# psc3_p8_ppca register map
Vendor: Infineon Technologies; Series: PSC3_P8; File version: 1.0
CPU: CM33 r0p1, little endian, MPU, FPU, DSP, VTOR, 3 interrupt priority bits, 143 interrupts
Registers are 32-bit, read-write, reset 0x0 unless marked. A register's access mark holds for its fields unless they carry their own. Offsets are from the block's base; [hi:lo] are bit positions; lines under a group give offsets from that group; {n}, {i} and the like mark numbered series; 'fields as' and 'values as' point back to an identical list; <NAME> marks a mode.

## SRSS (part 1 of 2) — SRSS Core Registers
Base 0x68200000
0x40 PWR_LVD_STATUS ro — High Voltage / Low Voltage Detector (HVLVD) Status Register
  [0] HVLVD1_OK — HVLVD1 output. 0: below voltage threshold 1: above voltage threshold
{0x100+4i} CLK_DSI_SELECT[{i}] (i=0..15) — Clock DSI Select Register
  [4:0] DSI_MUX — Selects a DSI source or low frequency clock for use in a clock path. The output of this mux can be selected for clock PATH<i> using CLK_SELECT_PATH register. Using the output of this mux as HFCLK source will result in undefined behavior. It can be used to clocks to DSI or as reference inputs for the FLL/PLL, subject to the frequency limits of those circuits. This mux is not glitch free, so do not change the selection while it is an actively selected clock.
    {v}=DSI_OUT{v} (DSI{v} - dsi_out[{v}]) (v=0..15); 16=ILO (ILO - Internal Low-speed Oscillator #0); 17=WCO (WCO - Watch-Crystal Oscillator); 18=ALTLF (ALTLF - Alternate Low-Frequency Clock); 19=PILO (PILO - Precision Internal Low-speed Oscillator); 20=ILO1 (ILO1 - Internal Low-speed Oscillator #1, if present.)
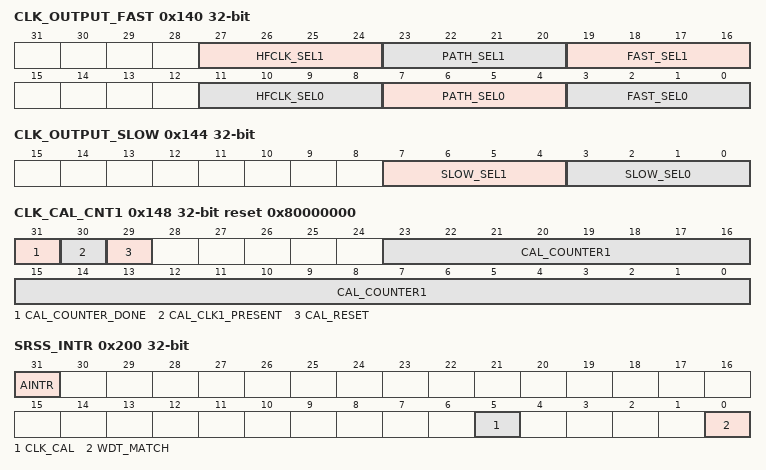
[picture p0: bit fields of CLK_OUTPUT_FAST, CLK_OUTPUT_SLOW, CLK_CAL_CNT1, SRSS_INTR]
0x140 CLK_OUTPUT_FAST — Fast Clock Output Select Register
  [27:24] HFCLK_SEL1 — Selects a HFCLK tree for use in fast clock output #1 logic
  [23:20] PATH_SEL1 — Selects a clock path to use in fast clock output #1 logic.
  [19:16] FAST_SEL1 — Select signal for fast clock output #1
    0=NC (Disabled - output is 0. For power savings, clocks are blocked before entering any muxes, including PATH_SEL1 and HFCLK_SEL1.); 1=ECO (External Crystal Oscillator (ECO)); 2=EXTCLK (External clock input (EXTCLK)); 3=ALTHF (Alternate High-Frequency (ALTHF) clock input to SRSS); 4=TIMERCLK (Timer clock. It is grouped with the fast clocks because it may be a gated version of a fast clock, and therefore may have a short high pulse.); 5=PATH_SEL1 (Selects the clock path chosen by PATH_SEL1 field); 6=HFCLK_SEL1 (Selects the output of the HFCLK_SEL1 mux); 7=SLOW_SEL1 (Selects the output of CLK_OUTPUT_SLOW.SLOW_SEL1); 8=IHO (Internal High-speed Oscillator (IHO).); 9=PWR (clk_pwr: used for PPU and related components)
  [11:8] HFCLK_SEL0 — Selects a HFCLK tree for use in fast clock output #0
  [7:4] PATH_SEL0 — Selects a clock path to use in fast clock output #0 logic.
  [3:0] FAST_SEL0 — Select signal for fast clock output #0
    0=NC (Disabled - output is 0. For power savings, clocks are blocked before entering any muxes, including PATH_SEL0 and HFCLK_SEL0.); 1=ECO (External Crystal Oscillator (ECO)); 2=EXTCLK (External clock input (EXTCLK)); 3=ALTHF (Alternate High-Frequency (ALTHF) clock input to SRSS); 4=TIMERCLK (Timer clock. It is grouped with the fast clocks because it may be a gated version of a fast clock, and therefore may have a short high pulse.); 5=PATH_SEL0 (Selects the clock path chosen by PATH_SEL0 field); 6=HFCLK_SEL0 (Selects the output of the HFCLK_SEL0 mux); 7=SLOW_SEL0 (Selects the output of CLK_OUTPUT_SLOW.SLOW_SEL0); 8=IHO (Internal High-speed Oscillator (IHO).); 9=PWR (clk_pwr: used for PPU and related components)
0x144 CLK_OUTPUT_SLOW — Slow Clock Output Select Register
  [7:4] SLOW_SEL1 — Select signal for slow clock output #1
    0=NC (Disabled - output is 0. For power savings, clocks are blocked before entering any muxes.); 1=ILO (Internal Low Speed Oscillator (ILO)); 2=WCO (Watch-Crystal Oscillator (WCO)); 3=BAK (Root of the Backup domain clock tree (BAK)); 4=ALTLF (Alternate low-frequency clock input to SRSS (ALTLF)); 5=LFCLK (Root of the low-speed clock tree (LFCLK)); 6=IMO (Internal Main Oscillator (IMO). This is grouped with the slow clocks so it can be observed during DEEPSLEEP entry/exit.); 7=SLPCTRL (Sleep Controller clock (SLPCTRL). This is grouped with the slow clocks so it can be observed during DEEPSLEEP entry/exit.); 8=PILO (Precision Internal Low Speed Oscillator (PILO)); 9=ILO1 (Internal Low Speed Oscillator (ILO1), if present on the product.); 10=ECO_PRESCALER (ECO Prescaler (ECO_PRESCALER)); 11=LPECO; 12=LPECO_PRESCALER (LPECO Prescaler (LPECO_PRESCALER)); 13=MFO (Medium Frequency Oscillator (MFO))
  [3:0] SLOW_SEL0 — Select signal for slow clock output #0
    values as SLOW_SEL1
0x148 CLK_CAL_CNT1 reset 0x80000000 — Clock Calibration Counter 1
  [31] CAL_COUNTER_DONE ro — Status bit indicating that the internal counter #1 is finished counting and CLK_CAL_CNT2.COUNTER stopped counting up
  [30] CAL_CLK1_PRESENT ro — Status bit indicating that a posedge was detected by counter #1. If this bit never asserts, there is no clock on counter #1 and CAL_COUNTER_DONE will stay low indefinitely. This can be recovered with CAL_RESET.
  [29] CAL_RESET — Reset clock calibration logic for window mode. This can be used to recover from unexpected conditions, such as no clock present on counter #1. Set this bit only when CLK_CAL_TEST.CAL_WINDOW_SEL=1 (window mode). It takes 3 clock cycles for reset to propagate.
  [23:0] CAL_COUNTER1 — Down-counter clocked on fast clock output #0 (see CLK_OUTPUT_FAST). This register always reads as zero. Counting starts internally when this register is written with a nonzero value. CAL_COUNTER_DONE goes immediately low to indicate that the counter has started and will be asserted when the counters are done. Do not write this field unless CAL_COUNTER_DONE==1. Both clocks must be running or the measurement will not complete, and this case can be recovered using CAL_RESET.
0x14C CLK_CAL_CNT2 ro — Clock Calibration Counter 2
  [23:0] CAL_COUNTER2 — Up-counter clocked on fast clock output #1 (see CLK_OUTPUT_FAST). When CLK_CAL_CNT1.CAL_COUNTER_DONE==1, the counter is stopped and can be read by SW. Do not read this value unless CAL_COUNTER_DONE==1. The expected final value is related to the ratio of clock frequencies used for the two counters and the value loaded into counter 1: CLK_CAL_CNT2.COUNTER=(F_cnt2/F_cnt1)*(CLK_CAL_CNT1.COUNTER)
0x200 SRSS_INTR — SRSS Interrupt Register
  [31] AINTR ro — See additional interrupts in SRSS_AINTR.
  [5] CLK_CAL write-1-clears — Clock calibration counter is done. This field is reset during DEEPSLEEP mode.
  [0] WDT_MATCH write-1-clears — WDT Interrupt Request. This bit is set each time WDT_COUNTR==WDT_MATCH. W1C also feeds the watch dog. Missing 2 interrupts in a row will generate a reset. Due to internal synchronization, it takes 2 SYSCLK cycles to update after a W1C. Interrupt state for WDT_MATCH remains valid throughout hibernate.
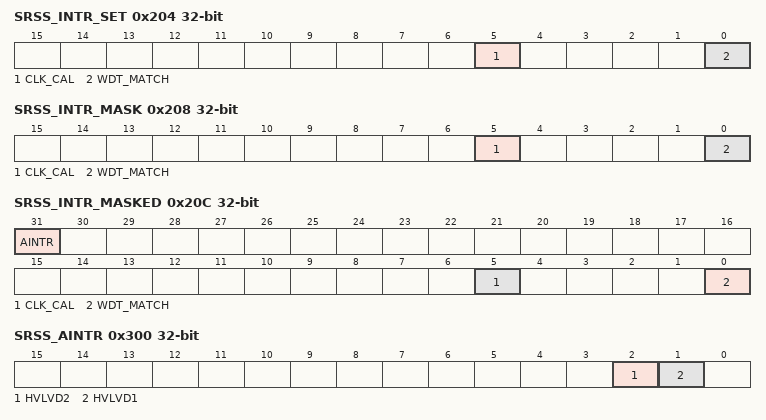
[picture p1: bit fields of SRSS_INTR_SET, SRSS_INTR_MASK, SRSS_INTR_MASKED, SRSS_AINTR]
0x204 SRSS_INTR_SET — SRSS Interrupt Set Register
  [5] CLK_CAL write-1-sets — Set interrupt for clock calibration counter done. This field is reset during DEEPSLEEP mode.
  [0] WDT_MATCH write-1-sets — Set interrupt for low voltage detector WDT_MATCH Interrupt state for WDT_MATCH remains valid throughout hibernate.
0x208 SRSS_INTR_MASK — SRSS Interrupt Mask Register
  [5] CLK_CAL — Mask for clock calibration done
  [0] WDT_MATCH — Mask for watchdog timer. Clearing this bit will not forward the interrupt to the CPU. It will not, however, disable the WDT reset generation on 2 missed interrupts. When WDT resets the chip, it also internally pends an interrupt that survives the reset. To prevent unintended ISR execution, clear SRSS_INTR.WDT_MATCH before setting this bit.
0x20C SRSS_INTR_MASKED ro — SRSS Interrupt Masked Register
  [31] AINTR — See additional MASKED bits in SRSS_AINTR_MASKED.ADDITIONAL
  [5] CLK_CAL — Logical and of corresponding request and mask bits.
  [0] WDT_MATCH — Logical and of corresponding request and mask bits.
0x300 SRSS_AINTR — SRSS Additional Interrupt Register
  [2] HVLVD2 write-1-clears — Interrupt for low voltage detector HVLVD2
  [1] HVLVD1 write-1-clears — Interrupt for low voltage detector HVLVD1
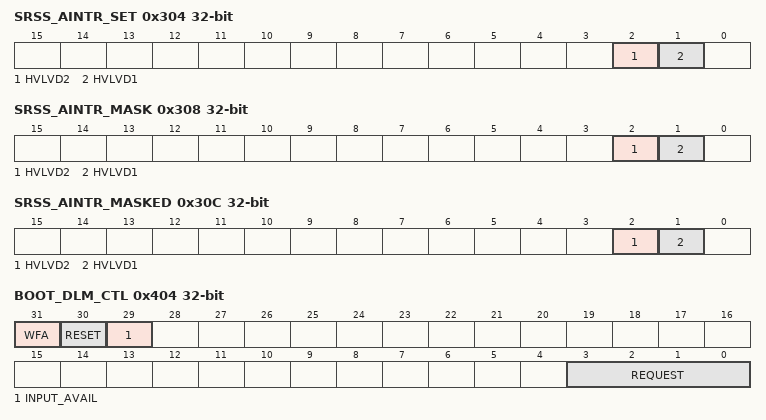
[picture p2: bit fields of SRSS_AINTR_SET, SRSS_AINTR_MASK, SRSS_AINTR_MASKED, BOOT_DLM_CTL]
0x304 SRSS_AINTR_SET — SRSS Additional Interrupt Set Register
  [2] HVLVD2 write-1-sets — Set interrupt for low voltage detector HVLVD2
  [1] HVLVD1 write-1-sets — Set interrupt for low voltage detector HVLVD1
0x308 SRSS_AINTR_MASK — SRSS Additional Interrupt Mask Register
  [2] HVLVD2 — Mask for low voltage detector HVLVD2
  [1] HVLVD1 — Mask for low voltage detector HVLVD1
0x30C SRSS_AINTR_MASKED ro — SRSS Additional Interrupt Masked Register
  [2] HVLVD2 — Logical and of corresponding request and mask bits.
  [1] HVLVD1 — Logical and of corresponding request and mask bits.
0x404 BOOT_DLM_CTL — Debug Control Register
  [31] WFA — Wait for Action. Set by BootROM when it waits for application or debug certificate to be loaded into the RAM. The bit must be cleared to continue BootROM operation. It is used by the Sys-AP.
  [30] RESET — Request the device reset after RAM application complete input parameters processing. This bit is analyzed with APP_INPUT_AVAIL so to take effect write both. 0 - No action, the device waits for input parameters. 1 - Reset the device after input parameters processing complete.
  [29] INPUT_AVAIL — Notify RAM application that input parameters are valid for processing: 0 - the input parameters are not available. 1 - the input parameters are available (ready) for processing.
  [3:0] REQUEST — A request to ROM_BOOT FW to execute particular code. This field survives some resets, including a system reset: * 0 - No request (default). * 1 - ROM_BOOT to wait for DLM app (PC=0). * 2 - ROM_BOOT to wait for an OEM debug token. * 3 - ROM_BOOT to wait for a PROT_FW debug token. * 4, 5 - ignored by ROM_BOOT. * 6 - ROM_BOOT to launch DLM app which has been downloaded by DFU. * 7 - ROM_BOOT to respond to DFU with DLM app status. Other: ignored by ROM_BOOT.
0x408 BOOT_DLM_CTL2 — Debug Control Register 2
  [31:0] APP_CTL — Address of application descriptor or debug certificate depends on DEBUG_TST_CTL.REQUEST. The application descriptor provides info about RAM application and its parameters layout in the staging area to BootROM and RAM application itself
0x40C BOOT_DLM_STATUS — Debug Status Register
  [31:0] DEBUG_STATUS — RAM application execution status. This status can be read by the debugger using Sys-AP or user application when RAM application completes with system reset. This field survives some resets, including a system reset.
0x410 RES_SOFT_CTL — Soft Reset Trigger Register
  [0] TRIGGER_SOFT write-1-sets — Triggers a soft reset. The reset clears this bit.
0x418 BOOT_STATUS — Boot Execution Status Register
  [31:0] DEBUG_STATUS — Boot execution status. This status register can be used for communication between ROM_BOOT and User Application. This status can be read by the debugger using Sys-AP or User Application. This field survives some resets, including a system reset.
0x430 BOOT_ENTRY — Warm Boot Entry Address
  [31:0] WARM_BOOT_ENTRY — Warm boot entry point. This status register can be used for communication between 2 software application before/after DS-RAM, DS-OFF or soft reset. This field survives low voltage resets, including a system reset.
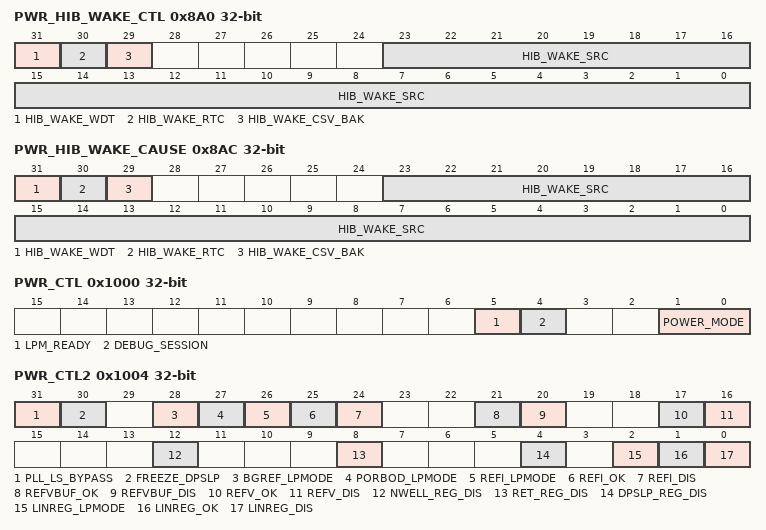
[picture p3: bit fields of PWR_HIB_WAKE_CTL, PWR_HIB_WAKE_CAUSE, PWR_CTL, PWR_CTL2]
0x8A0 PWR_HIB_WAKE_CTL — Hibernate Wakeup Mask Register
  [31] HIB_WAKE_WDT — When set, HIBERNATE will wakeup for a pending WDT interrupt.
  [30] HIB_WAKE_RTC — When set, HIBERNATE will wakeup for a pending RTC interrupt.
  [29] HIB_WAKE_CSV_BAK — When set, HIBERNATE will wakeup for CSV_BAK detection.
  [23:0] HIB_WAKE_SRC — When set, HIBERNATE will wakeup for the assigned source.
0x8A4 PWR_HIB_WAKE_CTL2 — Hibernate Wakeup Polarity Register
  [23:0] HIB_WAKE_SRC — Each bit selects the polarity for the corresponding HIBERNATE wakeup source. 0: Wakes when unmasked input is 0. 1: Wakes when unmasked input is 1.
0x8AC PWR_HIB_WAKE_CAUSE — Hibernate Wakeup Cause Register
  [31] HIB_WAKE_WDT write-1-clears — Indicates WDT wakeup cause. The WDT interrupt must be cleared before this bit can be cleared.
  [30] HIB_WAKE_RTC write-1-clears — Indicates RTC wakeup cause. The RTC interrupt must be cleared before this bit can be cleared.
  [29] HIB_WAKE_CSV_BAK write-1-clears — Indicates CSV_BAK wakeup cause. The related fault must be handled before this bit can be cleared.
  [23:0] HIB_WAKE_SRC write-1-clears — Each bit indicates a HIBERNATE wakeup cause. For each bit, writing a 1 clears the cause flag.
0x1000 PWR_CTL ro — Power Mode Control
  [5] LPM_READY — Indicates whether certain low power functions are ready. The low current circuits take longer to startup after XRES, HIBERNATE wakeup, or supply supervision reset wakeup than the normal mode circuits. HIBERNATE mode may be entered regardless of this bit. 0: If a low power circuit operation is requested, it will stay in its normal operating mode until it is ready. If DEEPSLEEP is requested by all processors WFI/WFE, the device will instead enter SLEEP. When low power circuits are ready, device will automatically enter the originally requested mode. 1: Normal operation. DEEPSLEEP and low power circuits operate as requested in other registers.
  [4] DEBUG_SESSION — Indicates whether a debug session is active (CDBGPWRUPREQ signal is 1)
    0=NO_SESSION (No debug session active); 1=SESSION_ACTIVE (Debug session is active. Power modes behave differently to keep the debug session active, and current consumption may be higher than datasheet specification.)
  [1:0] POWER_MODE — Current power mode of the device. Note that this field cannot be read in all power modes on actual silicon.
    0=RESET (System is resetting.); 1=ACTIVE (At least one CPU is running.); 2=SLEEP (No CPUs are running. Peripherals may be running.); 3=DEEPSLEEP (Main high-frequency clock is off; low speed clocks are available. Communication interface clocks may be present.)
0x1004 PWR_CTL2 — Power Mode Control 2
  [31] PLL_LS_BYPASS — Bypass level shifter inside the PLL. Unused, if no PLL is present in the product. Note that this only applies to PLL200M. 0: Do not bypass the level shifter. This setting is ok for all operational modes and vccd target voltage. 1: Bypass the level shifter. This may reduce jitter on the PLL output clock, but can only be used when vccd is targeted to 1.1V nominal. Otherwise, it can result in clock degradation and static current.
  [30] FREEZE_DPSLP write-1-clears — Controls whether mode and state of GPIOs and SIOs in the system are frozen. This is intended to be used as part of the DEEPSLEEP-RAM and DEEPSLEEP-OFF entry and exit sequences. It is set by HW while entering DEEPSLEEP-RAM and DEEPSLEEP-OFF modes. Writing a 1 clears freeze and GPIOs and SIOs resume normal operation.
  [28] BGREF_LPMODE — Control the circuit-level power mode of the Bandgap Reference circuits for higher operating modes than DEEPSLEEP. This selects a second set of bandgap voltage and current generation circuits that are optimized for low current consumption. The low current circuits are automatically used in DEEPSLEEP mode regardless of this bit. The value in this register is ignored and higher-current mode is used until LPM_READY==1. After this bit is set, the Active Reference circuit can be disabled to reduce current (ACT_REF_DIS=0). Firmware is responsible to enable the Active Reference and ensure ACT_REF_OK==1 before changing back to higher current mode. This register is only reset by XRES, HIBERNATE wakeup, or supply supervision reset. 0: Bandgap Reference uses the normal settings. 1: Bandgap Reference uses the low power DeepSleep circuits. Power supply rejection is reduced to save current.
  [27] PORBOD_LPMODE — Control the power mode of the POR/BOD circuits. The value in this register is ignored and normal mode is used until LPM_READY==1. This register is only reset by XRES, HIBERNATE wakeup, or supply supervision reset. 0: POR/BOD circuits operate in normal mode. 1: POR/BOD circuits operate in low power mode. Response time is reduced to save current.
  [26] REFI_LPMODE — Control the power mode of the reference current generator. The value in this register is ignored and normal mode is used until LPM_READY==1. This register is only reset by XRES, HIBERNATE wakeup, or supply supervision reset. 0: Current reference generator operates in normal mode. 1: Current reference generator operates in low power mode. Response time is reduced to save current.
  [25] REFI_OK ro — Indicates that the current reference is ready. Due to synchronization delays, it may take two IMO clock cycles for hardware to clear this bit after asserting REFI_DIS=1.
  [24] REFI_DIS
  [21] REFVBUF_OK ro — Indicates that the voltage reference buffer is ready. Due to synchronization delays, it may take two IMO clock cycles for hardware to clear this bit after asserting REFVBUF_DIS=1.
  [20] REFVBUF_DIS — Disable the voltage reference buffer. Firmware should only disable the buffer when there is no connected circuit that is using it. SRSS circuits that require it are the PLL and ECO. A particular product may have circuits outside the SRSS that use the buffer. This register is only reset by XRES, HIBERNATE wakeup, or supply supervision reset.
  [17] REFV_OK ro — Indicates that the normal mode of the voltage reference is ready.
  [16] REFV_DIS
  [12] NWELL_REG_DIS — Explicitly disable the Nwell regulator. This register should normally be zero, except for special sequences provided by Infineon to use a different regulator. This register is only reset by XRES, HIBERNATE wakeup, or supply supervision reset. 0: Nwell Regulator is on. Hardware disables it automatically for internal sequences, including for HIBERNATE and XRES low power modes. Hardware keeps the Nwell Regulator enabled during ACTIVE/SLEEP modes, so it is ready to enter DEEPSLEEP at any time. 1: Nwell Regulator is explicitly disabled. Only use this for special cases when another source supplies vnwell during DEEPSLEEP mode. This setting is only legal when another source supplies vnwell, but there is no special hardware protection for this case.
  [8] RET_REG_DIS — Explicitly disable the Retention regulator. This field should normally be zero, except for special sequences provided by Infineon to use a different regulator. This register is only reset by XRES, HIBERNATE wakeup, or supply supervision reset. 0: Retention Regulator is not explicitly disabled. Hardware disables it automatically for internal sequences, including for HIBERNATE and XRES low power modes. Hardware keeps the Retention Regulator enabled during ACTIVE/SLEEP modes, so it is ready to enter DEEPSLEEP at any time. 1: Retention Regulator is explicitly disabled. Only use this for special cases when another source supplies vccret during DEEPSLEEP mode. This setting is only legal when another source supplies vccret, but there is no special hardware protection for this case.
  [4] DPSLP_REG_DIS — Explicity disable the DeepSleep regulator, including circuits shared with the Active Regulator. This register must not be set except as part of an Infineon-provided sequence or API. This register is only reset by XRES, HIBERNATE wakeup, or supply supervision reset. 0: DeepSleep Regulator is not explicitly disabled. This is the normal setting, and hardware automatically controls the DeepSleep regulator for most sequences, including for HIBERNATE and XRES low power modes. This setting must be used if the Active Linear Regulator is used, because some circuitry is shared. 1: DeepSleep Regulator is explicitly disabled. Only use this for special cases as part of an Infineon-provided handoff to another supply source. For example, this setting may be used when another source supplies vccdpslp during DEEPSLEEP mode and the Active Linear Regulator is not usedfor ACTIVE/SLEEP modes.
  [2] LINREG_LPMODE — Control the power mode of the Linear Regulator. The value in this register is ignored and normal mode is used until LPM_READY==1. This register is only reset by XRES, HIBERNATE wakeup, or supply supervision reset. 0: Linear Regulator operates in normal mode. 1: Linear Regulator operates in low power mode. Load current capability is reduced, and firmware must ensure the current is kept within the limit.
  [1] LINREG_OK ro — Status of the linear Core Regulator.
  [0] LINREG_DIS — Explicitly disable the linear Core Regulator. Write zero for Traveo II devices. This register is only reset by XRES, HIBERNATE wakeup, or supply supervision reset. 0: Linear Core Regulator is not explicitly disabled. Hardware disables it automatically for internal sequences, including for DEEPSLEEP, HIBERNATE, and XRES low power modes. 1: Linear Core Regulator is explicitly disabled. Only use this for special cases when another source supplies vccd during ACTIVE and SLEEP modes. This setting is only legal when another source supplies vccd, but there is no special hardware protection for this case.
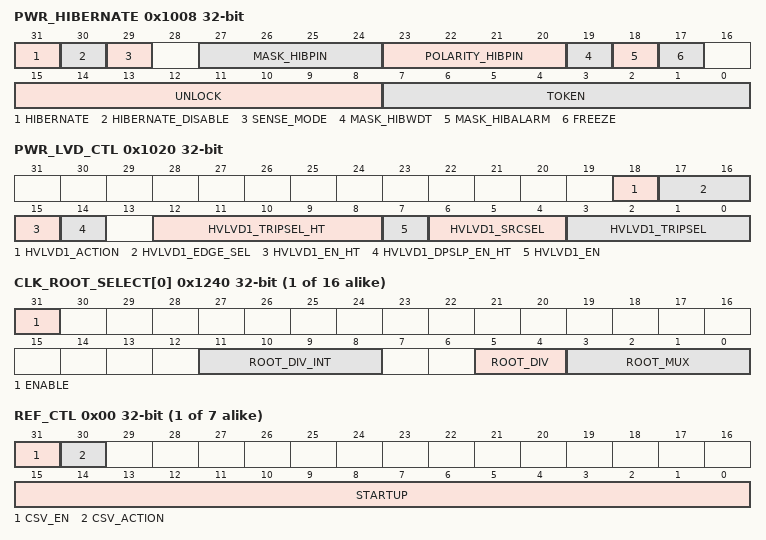
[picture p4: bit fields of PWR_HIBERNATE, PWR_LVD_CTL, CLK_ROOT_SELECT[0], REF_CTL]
0x1008 PWR_HIBERNATE — HIBERNATE Mode Register
  [31] HIBERNATE — Firmware sets this bit to enter HIBERNATE mode. The system will enter HIBERNATE mode immediately after writing to this bit and will wakeup only in response to XRES or WAKEUP. Both UNLOCK and FREEZE must have been set correctly in a previous write operations. Otherwise, it will not enter HIBERNATE. External supplies must have been stable for 250us before entering HIBERNATE mode.
  [30] HIBERNATE_DISABLE write-1-sets — Hibernate disable bit. 0: Normal operation, HIBERNATE works as described 1: Further writes to this register are ignored Note: This bit is a write-once bit until the next reset. Avoid changing any other bits in this register while disabling HIBERNATE mode. Also, it is recommended to clear the UNLOCK code, if it was previously written..
  [29] SENSE_MODE write-1-sets — Power mode when wakeups are sensitive. The default of this field is 0 for software compatibility with other products. It is recommended to set this field to 1 for new/updated software. 0: Wakeups are sensitive only during HIBERNATE mode. A wakeup pulse that comes just before HIBERNATE entry may be missed. Backward compatible. 1: Wakeups are sensitive in HIBERNATE and higher modes. Before entering HIBERNATE, software must clear all unmasked, pending wakeups in PWR_HIB_WAKE_CAUSE register. An unmasked, pending wakeup causes HIBERNATE wakeup, even if it was pending from before HIBERNATE entry. This prevents missed wakeups.
  [27:24] MASK_HIBPIN
  [23:20] POLARITY_HIBPIN
  [19] MASK_HIBWDT
  [18] MASK_HIBALARM
  [17] FREEZE — Controls whether mode and state of GPIOs and SIOs in the system are frozen. This is intended to be used as part of the HIBERNATE entry and exit sequences. When entering HIBERNATE mode, the first write instructs DEEPSLEEP peripherals that they cannot ignore the upcoming freeze command. This occurs even in the illegal condition where UNLOCK is not set. If UNLOCK and HIBERNATE are properly set, the IOs actually freeze on the second write. Supply supervision is disabled during HIBERNATE mode. HIBERNATE peripherals ignore resets (excluding XRES) while FREEZE==1.
  [15:8] UNLOCK — This byte must be set to 0x3A for FREEZE or HIBERNATE fields to operate. Any other value in this register will cause FREEZE/HIBERNATE to have no effect, except as noted in the FREEZE description.
  [7:0] TOKEN — Contains a 8-bit token that is retained through a HIBERNATE/WAKEUP sequence that can be used by firmware to differentiate WAKEUP from a general RESET event. Note that waking up from HIBERNATE using XRES will reset this register.
0x1020 PWR_LVD_CTL — High Voltage / Low Voltage Detector (HVLVD) Configuration Register
  [18] HVLVD1_ACTION — Action taken when the threshold is crossed in the programmed directions(s)
    0=INTERRUPT (Generate an interrupt); 1=FAULT (Generate a fault)
  [17:16] HVLVD1_EDGE_SEL — Sets which edge(s) will trigger an action when the threshold is crossed.
    0=DISABLE (Disabled); 1=RISING (Rising edge); 2=FALLING (Falling edge); 3=BOTH (Both rising and falling edges)
  [15] HVLVD1_EN_HT — Enable HVLVD1 voltage monitor. This detector monitors vddd only. Do not change other HVLVD1 settings when enabled.
  [14] HVLVD1_DPSLP_EN_HT — Keep HVLVD1 voltage monitor enabled during DEEPSLEEP mode. This field is only used when HVLVD1_EN_HT==1.
  [12:8] HVLVD1_TRIPSEL_HT
  [7] HVLVD1_EN — Enable HVLVD1 voltage monitor. HVLVD1 does not function during DEEPSLEEP, but it automatically returns to its configured setting after DEEPSLEEP wakeup. Do not change other HVLVD1 settings when enabled.
  [6:4] HVLVD1_SRCSEL — Source selection for HVLVD1
    0=VDDD (Select VDDD); 1=AMUXBUSA (Select AMUXBUSA (VDDD branch)); 2=RSVD (N/A); 3=VDDIO (N/A); 4=AMUXBUSB (Select AMUXBUSB (VDDD branch))
  [3:0] HVLVD1_TRIPSEL — Threshold selection for HVLVD1. Disable the detector (HVLVD1_EN=0) before changing the threshold. 0: rise=1.225V (nom), fall=1.2V (nom) 1: rise=1.425V (nom), fall=1.4V (nom) 2: rise=1.625V (nom), fall=1.6V (nom) 3: rise=1.825V (nom), fall=1.8V (nom) 4: rise=2.025V (nom), fall=2V (nom) 5: rise=2.125V (nom), fall=2.1V (nom) 6: rise=2.225V (nom), fall=2.2V (nom) 7: rise=2.325V (nom), fall=2.3V (nom) 8: rise=2.425V (nom), fall=2.4V (nom) 9: rise=2.525V (nom), fall=2.5V (nom) 10: rise=2.625V (nom), fall=2.6V (nom) 11: rise=2.725V (nom), fall=2.7V (nom) 12: rise=2.825V (nom), fall=2.8V (nom) 13: rise=2.925V (nom), fall=2.9V (nom) 14: rise=3.025V (nom), fall=3.0V (nom) 15: rise=3.125V (nom), fall=3.1V (nom)
{0x1200+4i} CLK_PATH_SELECT[{i}] (i=0..15) — Clock Path Select Register
  [2:0] PATH_MUX — Selects a source for clock PATH<i>. Note that not all products support all clock sources. Selecting a clock source that is not supported will result in undefined behavior. It takes four cycles of the originally selected clock to switch away from it. Do not disable the original clock during this time.
    0=IMO (IMO - Internal R/C Oscillator); 1=EXTCLK (EXTCLK - External Clock Pin); 2=ECO (ECO - External-Crystal Oscillator); 3=ALTHF (ALTHF - Alternate High-Frequency clock input (product-specific clock)); 4=DSI_MUX (DSI_MUX - Output of DSI mux for this path. Using a DSI source directly as root of HFCLK will result in undefined behavior.); 5=LPECO (LPECO - Low-Power External-Crystal Oscillator); 6=IHO (IHO - Internal High-speed Oscillator)
{0x1240+4i} CLK_ROOT_SELECT[{i}] (i=0..15) — Clock Root Select Register
  [31] ENABLE — Enable for this clock root. All clock roots default to disabled (ENABLE==0) except HFCLK0, which cannot be disabled.
  [11:8] ROOT_DIV_INT — Selects predivider value for this clock root and DSI input. This divider is after DIRECT_MUX. For products with DSI, the output of this mux is routed to DSI for use as a signal. For products with clock supervision, the output of this mux is the monitored clock for CSV_HF<k>.
    0=NO_DIV (Transparent mode, feed through selected clock source w/o dividing.); {v}=DIV_BY_{v+1} (Divide selected clock source by {v+1}) (v=1..15)
  [5:4] ROOT_DIV — Obsolete. Do not use in new designs.
  [3:0] ROOT_MUX — Selects a clock path for HFCLK<k> and SRSS DSI input <k>. The output of this mux goes to the direct mux (see CLK_DIRECT_SELECT). Use CLK_SELECT_PATH[i] to configure the desired path. The number of clock paths is product-specific, and selecting an unimplemented path is not supported. Some paths may have FLL or PLL available (product-specific), and the control and bypass mux selections of these are in other registers. Configure the FLL using CLK_FLL_CONFIG register. Configure a PLL using the related CLK_PLL_CONFIG[k] register. Note that not all products support all clock sources. Selecting a clock source that is not supported will result in undefined behavior. It takes four cycles of the originally selected clock to switch away from it. Do not disable the original clock during this time.
    {v}=PATH{v} (Select PATH{v}) (v=0..15)
{0x1280+4i} CLK_DIRECT_SELECT[{i}] (i=0..15) — Clock Root Direct Select Register
  [8] DIRECT_MUX — Direct selection mux that allows IMO to bypass most of the clock mux structure. For products with multiple regulators, this mux can be used to reduce current without requiring significant reconfiguration of the clocking network. The default value of HFCLK<0>==ROOT_MUX, and the default value for other clock trees is product-specific.
    0=IMO (Select IMO); 1=ROOT_MUX (Select ROOT_MUX selection)
0x1400 CSV_HF group — Clock Supervisor (CSV) registers for Root clocks
  {0x0+0x10*j} CSV[{j}] (j=0..6) group — Active domain Clock Supervisor (CSV) registers
    0x00 REF_CTL — Clock Supervision Reference Control
      [31] CSV_EN — Enables clock supervision, both frequency and loss. CSV in Active domain: Clock supervision is reset during DeepSleep and Hibernate modes. When enabled it begins operating automatically after a DeepSleep wakeup, but it must be reconfigured after Hibernate wakeup. CSV in DeepSleep domain: Clock supervision is reset during Hibernate mode. It must be reconfigured after Hibernate wakeup. A CSV error detection is reported to the Fault structure, or instead it can generate a power reset.
      [30] CSV_ACTION — Specifies the action taken when an anomaly is detected on the monitored clock. CSV in DeepSleep domain always do a Fault report (which also wakes up the system).
        0=FAULT (Generate a fault); 1=RESET (Cause a power reset. This should only be used for clk_hf0.)
      [15:0] STARTUP — Startup delay time -1 (in reference clock cycles), after enable or DeepSleep wakeup, from reference clock start to monitored clock start. At a minimum (both clocks running): STARTUP >= (PERIOD +3) * FREQ_RATIO - UPPER, with FREQ_RATIO = (Reference frequency / Monitored frequency) On top of that the actual clock startup delay and the margin for accuracy of both clocks must be added.
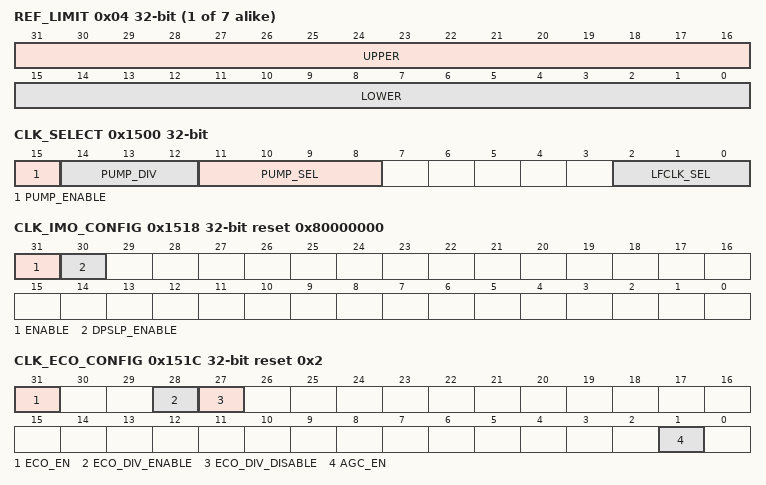
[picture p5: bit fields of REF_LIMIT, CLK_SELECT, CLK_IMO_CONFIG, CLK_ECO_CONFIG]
    0x04 REF_LIMIT — Clock Supervision Reference Limits
      [31:16] UPPER — Cycle time upper limit. Set the upper limit -1, in reference clock cycles, before (or same time) the next monitored clock event must happen. If a monitored clock event does not happen before this limit is reached, or does not happen at all (clock loss), a CSV error is detected.
      [15:0] LOWER — Cycle time lower limit. Set the lower limit -1, in reference clock cycles, before the next monitored clock event is allowed to happen. If a monitored clock event happens before this limit is reached a CSV error is detected. LOWER must be at least 1 less than UPPER. In case the clocks are asynchronous LOWER must be at least 3 less than UPPER.
    0x08 MON_CTL — Clock Supervision Monitor Control
      [15:0] PERIOD — Period time. Set the Period -1, in monitored clock cycles, before the next monitored clock event happens. PERIOD <= (UPPER+1) / FREQ_RATIO -1, with FREQ_RATIO = (Reference frequency / Monitored frequency) In case the clocks are asynchronous: PERIOD <= UPPER / FREQ_RATIO -1 Additionally margin must be added for accuracy of both clocks.
0x1500 CLK_SELECT — Clock selection register
  [15] PUMP_ENABLE — Enable the pump clock. PUMP_ENABLE and the PUMP_SEL mux are not glitch-free to minimize side-effects, avoid changing the PUMP_SEL and PUMP_DIV while changing PUMP_ENABLE. To change the settings, do the following: 1) If the pump clock is enabled, write PUMP_ENABLE=0 without changing PUMP_SEL and PUMP_DIV. 2) Change PUMP_SEL and PUMP_DIV to desired settings with PUMP_ENABLE=0. 3) Write PUMP_ENABLE=1 without changing PUMP_SEL and PUMP_DIV.
  [14:12] PUMP_DIV — Division ratio for PUMPCLK. Uses selected PUMP_SEL clock as the source.
    0=NO_DIV (Transparent mode, feed through selected clock source w/o dividing.); 1=DIV_BY_2 (Divide selected clock source by 2); 2=DIV_BY_4 (Divide selected clock source by 4); 3=DIV_BY_8 (Divide selected clock source by 8); 4=DIV_BY_16 (Divide selected clock source by 16)
  [11:8] PUMP_SEL — Selects clock PATH<k>, where k=PUMP_SEL. The output of this mux goes to the PUMP_DIV to make PUMPCLK Each product has a specific number of available clock paths. Selecting a path that is not implemented on a product will result in undefined behavior. Note that this is not a glitch free mux.
  [2:0] LFCLK_SEL — Select source for LFCLK. Note that not all products support all clock sources. Selecting a clock source that is not supported will result in undefined behavior. Writes to this field are ignored unless the WDT is unlocked using WDT_LOCK register. It takes four cycles of the originally selected clock to switch away from it. Do not disable the original clock during this time.
    0=ILO (ILO - Internal Low-speed Oscillator); 1=WCO (WCO - Watch-Crystal Oscillator. Requires Backup domain to be present and properly configured (including external watch crystal, if used).); 2=ALTLF (ALTLF - Alternate Low-Frequency Clock. Capability is product-specific); 3=PILO (PILO - Precision ILO, if present.); 4=ILO1 (ILO1 - Internal Low-speed Oscillator #1, if present.); 5=ECO_PRESCALER (ECO_PRESCALER - External-Crystal Oscillator after prescaling, if present. Does not work in DEEPSLEEP or HIBERNATE modes. Intended for applications that operate in ACTIVE/SLEEP modes only. This option is only valid when ECO is present in the product. Not compatible with an clk_sys frequency <48MHz.); 6=LPECO_PRESCALER (LPECO_PRESCALER - Low-Power External-Crystal Oscillator after prescaling, if present. This choice works in ACTIVE/SLEEP/DEEPSLEEP modes. This option is only valid when LPECO is present in the product.)
0x1518 CLK_IMO_CONFIG reset 0x80000000 — IMO Configuration
  [31] ENABLE — Master enable for IMO oscillator. This bit must be high at all times for all functions to work properly. Hardware will automatically disable the IMO during HIBERNATE and XRES. It will automatically disable during DEEPSLEEP if DPSLP_ENABLE==0.
  [30] DPSLP_ENABLE — Enable for IMO during DEEPSLEEP. This bit configures IMO behavior during DEEPSLEEP: 0: IMO is automatically disabled during DEEPSLEEP and enables upon wakeup; 1: IMO is kept enabled throughout DEEPSLEEP
0x151C CLK_ECO_CONFIG reset 0x2 — ECO Configuration Register
  [31] ECO_EN — Master enable for ECO oscillator. Configure the settings in CLK_ECO_CONFIG2 to work with the selected crystal, before enabling ECO.
  [28] ECO_DIV_ENABLE — ECO prescaler enable command (mutually exclusive with ECO_DIV_DISABLE). ECO Prescaler only works in ACTIVE and SLEEP modes. SW sets this field to '1' to enable the divider and HW sets this field to '0' to indicate that divider enabling has completed. When the divider is enabled, its integer and fractional counters are initialized to '0'. If a divider is to be re-enabled using different integer and fractional divider values, the SW should follow these steps: 0: Disable the divider using the ECO_DIV_DISABLE field. 1: Configure CLK_ECO_PRESCALE registers. 2: Enable the divider using the ECO_DIV_ENABLE field. HW sets the ECO_DIV_ENABLE field to '0' when the enabling is performed and HW set CLK_ECO_PRESCALER.ENABLED to '1' when the enabling is performed.
  [27] ECO_DIV_DISABLE — ECO prescaler disable command (mutually exclusive with ECO_DIV_ENABLE). SW sets this field to '1' and HW sets this field to '0'. HW sets ECO_DIV_DISABLE field to '0' immediately and HW sets CLK_ECO_PRESCALE.ECO_DIV_EN field to '0' immediately.
  [1] AGC_EN — Automatic Gain Control (AGC) enable. When set, the oscillation amplitude is controlled to the level selected by CLK_ECO_CONFIG2.ATRIM. When low, the amplitude is not explicitly controlled and can be as high as the vddd supply. WARNING: use care when disabling AGC because driving a crystal beyond its rated limit can permanently damage the crystal.
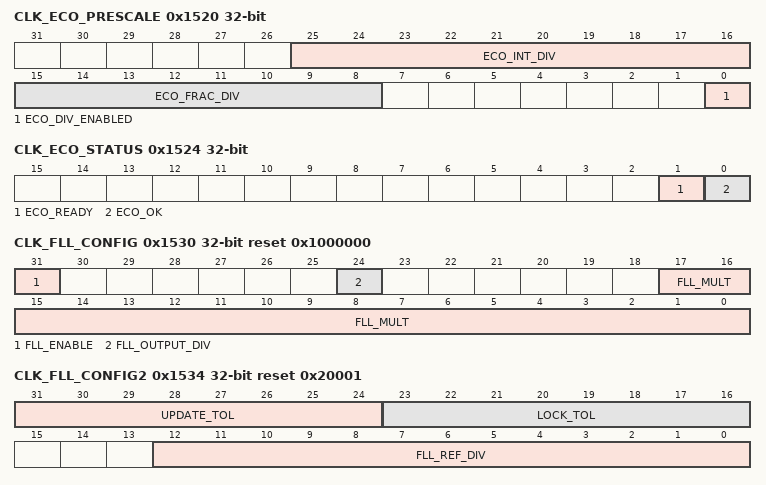
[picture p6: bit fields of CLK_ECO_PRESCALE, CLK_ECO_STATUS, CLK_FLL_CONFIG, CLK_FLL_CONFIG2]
0x1520 CLK_ECO_PRESCALE — ECO Prescaler Configuration Register
  [25:16] ECO_INT_DIV — 10-bit integer value allows for ECO frequencies up to 33.55MHz. Subtract one from the desired divide value when writing this field. For example, to divide by 1, write ECO_INT_DIV=0. Do not change this setting when ECO Prescaler is enabled.
  [15:8] ECO_FRAC_DIV — 8-bit fractional value, sufficient to get prescaler output within the +/-65ppm calibration range. Subtract one from the desired divide value when writing this field. For example, to divide by 1, write ECO_FRAC_DIV=0. Do not change this setting when ECO Prescaler is enabled.
  [0] ECO_DIV_ENABLED ro — ECO prescaler enabled. HW sets this field to '1' as a result of an CLK_ECO_CONFIG.ECO_DIV_ENABLE command. HW sets this field to '0' as a result on a CLK_ECO_CONFIG.ECO_DIV_DISABLE command. ECO prescaler is incompatible with DEEPSLEEP modes, and firmware must disable it before entering DEEPSLEEP.
0x1524 CLK_ECO_STATUS ro — ECO Status Register
  [1] ECO_READY — Indicates the ECO internal oscillator circuit has had enough time to fully stabilize. This is the output of a counter since ECO was enabled, and it does not check the ECO output. It is recommended to also confirm ECO_OK==1.
  [0] ECO_OK — Indicates the ECO internal oscillator circuit has sufficient amplitude. It may not meet the PPM accuracy or duty cycle spec.
0x1530 CLK_FLL_CONFIG reset 0x1000000 — FLL Configuration Register
  [31] FLL_ENABLE — Master enable for FLL. The FLL requires firmware sequencing when enabling and disabling. Hardware handles sequencing automatically when entering/exiting DEEPSLEEP. To enable the FLL, use the following sequence: 1) Configure FLL and CCO settings. Do not modify CLK_FLL_CONFIG3.BYPASS_SEL (must be AUTO) or CLK_FLL_CONFIG.FLL_ENABLE (must be 0). 2) Enable the CCO by writing CLK_FLL_CONFIG4.CCO_ENABLE=1 3) Wait until CLK_FLL_STATUS.CCO_READY==1. 4) Ensure the reference clock has stabilized. 5) Write FLL_ENABLE=1. 6) Optionally wait until CLK_FLL_STATUS.LOCKED==1. The hardware automatically changes to the FLL output when LOCKED==1. To disable the FLL, use the following sequence: 1) Write CLK_FLL_CONFIG3.BYPASS_SEL=FLL_REF. 2) Read CLK_FLL_CONFIG3.BYPASS_SEL to ensure the write completes (read is not optional). 3) Wait at least ten cycles of either FLL reference clock or FLL output clock, whichever is slower. 4) Disable FLL with FLL_ENABLE=0. 5) Disable the CCO by writing CLK_FLL_CONFIG4.CCO_ENABLE=0. 6) Write CLK_FLL_CONFIG3.BYPASS_SEL=AUTO. 7) Read CLK_FLL_CONFIG3.BYPASS_SEL to ensure the write completes (read is not optional). 8) Wait three cycles of FLL reference clock. 0: Block is powered off 1: Block is powered on
  [24] FLL_OUTPUT_DIV — Control bits for Output divider. Set the divide value before enabling the FLL, and do not change it while FLL is enabled. 0: no division 1: divide by 2
  [17:0] FLL_MULT — Multiplier to determine CCO frequency in multiples of the frequency of the selected reference clock (Fref). Ffll = (FLL_MULT) * (Fref / REFERENCE_DIV) / (OUTPUT_DIV+1)
0x1534 CLK_FLL_CONFIG2 reset 0x20001 — FLL Configuration Register 2
  [31:24] UPDATE_TOL — Update tolerance sets the error threshold for when the FLL will update the CCO frequency settings. The update tolerance is the allowed difference between the count value for the ideal formula and the measured value. UPDATE_TOL should be less than LOCK_TOL.
  [23:16] LOCK_TOL — Lock tolerance sets the error threshold for when the FLL output is considered locked to the reference input. A high tolerance can be used to lock more quickly or allow less accuracy. The tolerance is the allowed difference between the count value for the ideal formula and the measured value. 0: tolerate error of 1 count value 1: tolerate error of 2 count values ... 255: tolerate error of 256 count values
  [12:0] FLL_REF_DIV — Control bits for reference divider. Set the divide value before enabling the FLL, and do not change it while FLL is enabled. 0: illegal (undefined behavior) 1: divide by 1 ... 8191: divide by 8191
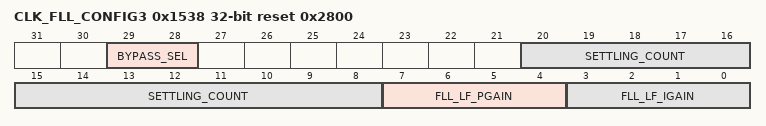
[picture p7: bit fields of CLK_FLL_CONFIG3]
0x1538 CLK_FLL_CONFIG3 reset 0x2800 — FLL Configuration Register 3
  [29:28] BYPASS_SEL — Bypass mux located just after FLL output. This register can be written while the FLL is enabled. When changing BYPASS_SEL, do not turn off the reference clock or CCO clock for five cycles (whichever is slower). Whenever BYPASS_SEL is changed, it is required to read CLK_FLL_CONFIG3 to ensure the change takes effect.
    0=AUTO (Automatic using lock indicator. When unlocked, automatically selects FLL reference input (bypass mode). When locked, automatically selects FLL output. This can allow some processing to occur while the FLL is locking, such as after DEEPSLEEP wakeup. It is incompatible with clock supervision, because the frequency changes based on the lock signal.); 1=LOCKED_OR_NOTHING (Similar to AUTO, except the clock is gated off when unlocked. This is compatible with clock supervision, because the supervisors allow no clock during startup (until a timeout occurs), and the clock targets the proper frequency whenever it is running.); 2=FLL_REF (Select FLL reference input (bypass mode). Ignores lock indicator); 3=FLL_OUT (Select FLL output. Ignores lock indicator.)
  [20:8] SETTLING_COUNT — Number of undivided reference clock cycles to wait after changing the CCO trim until the loop measurement restarts. A delay allows the CCO output to settle and gives a more accurate measurement. The default is tuned to an 8MHz reference clock since the IMO is expected to be the most common use case. 0: no settling time 1: wait one reference clock cycle ... 8191: wait 8191 reference clock cycles
  [7:4] FLL_LF_PGAIN — FLL Loop Filter Gain Setting #2. The proportional gain is the sum of FLL_LF_IGAIN and FLL_LF_PGAIN. 0: 1/256 1: 1/128 2: 1/64 3: 1/32 4: 1/16 5: 1/8 6: 1/4 7: 1/2 8: 1.0 9: 2.0 10: 4.0 11: 8.0 >=12: illegal
  [3:0] FLL_LF_IGAIN — FLL Loop Filter Gain Setting #1. The proportional gain is the sum of FLL_LF_IGAIN and FLL_LF_PGAIN. 0: 1/256 1: 1/128 2: 1/64 3: 1/32 4: 1/16 5: 1/8 6: 1/4 7: 1/2 8: 1.0 9: 2.0 10: 4.0 11: 8.0 >=12: illegal
